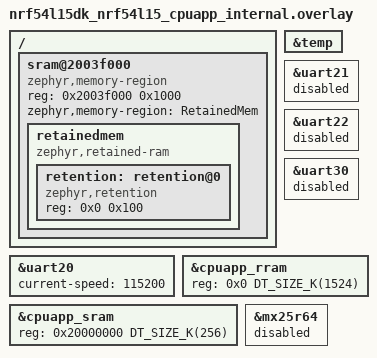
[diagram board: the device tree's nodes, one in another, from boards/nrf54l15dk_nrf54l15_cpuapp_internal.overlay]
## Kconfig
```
mainmenu "nRF54 Soil Moisture Sensor Configuration"

config APP_TEMPERATURE_MONITORING
	bool "Enable temperature monitoring"
	default y
	select SENSOR
	help
	  Enable internal die temperature sensor monitoring.

config APP_MEASUREMENT_INTERVAL_SEC
	int "Measurement interval (seconds)"
	default 300
	help
	  Time between periodic measurements. Device sleeps between readings.


if OPENTHREAD

choice OPENTHREAD_NORDIC_LIBRARY_CONFIGURATION
	default OPENTHREAD_NORDIC_LIBRARY_MTD
endchoice

choice OPENTHREAD_DEVICE_TYPE
	default OPENTHREAD_MTD
endchoice

endif # OPENTHREAD

source "${ZEPHYR_CONNECTEDHOMEIP_MODULE_DIR}/config/nrfconnect/chip-module/Kconfig.features"
source "${ZEPHYR_CONNECTEDHOMEIP_MODULE_DIR}/config/nrfconnect/chip-module/Kconfig.defaults"
source "Kconfig.zephyr"
```

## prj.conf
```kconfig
# nRF54 Soil Moisture Sensor - Debug Configuration
# Development build with full logging

# Application features
CONFIG_APP_TEMPERATURE_MONITORING=y
CONFIG_APP_MEASUREMENT_INTERVAL_SEC=10

# Enable CHIP
CONFIG_CHIP=y
CONFIG_CHIP_DEVICE_PRODUCT_ID=32781
CONFIG_CHIP_PROJECT_CONFIG="src/chip_project_config.h"
CONFIG_STD_CPP17=y
CONFIG_THREAD_NAME=y
CONFIG_MPU_STACK_GUARD=y
CONFIG_CHIP_LIB_SHELL=y
CONFIG_CHIP_ENABLE_PAIRING_AUTOSTART=y

# Enable Intermittently Connected Device support,
# with Long Idle Time to reduce power usage
CONFIG_CHIP_ENABLE_ICD_SUPPORT=y
CONFIG_CHIP_ICD_LIT_SUPPORT=y

# Enable Matter extended announcement and increase duration to 1 hour
CONFIG_CHIP_BLE_EXT_ADVERTISING=y
CONFIG_CHIP_BLE_ADVERTISING_DURATION=60

# OpenThread shell for debugging
CONFIG_OPENTHREAD_SHELL=y
CONFIG_SHELL_BACKEND_SERIAL_RX_RING_BUFFER_SIZE=256

# GRTC timer for wakeup from System OFF
CONFIG_NRF_GRTC_TIMER=y

# RAM retention in System OFF
CONFIG_RETAINED_MEM=y
CONFIG_RETAINED_MEM_MUTEX_FORCE_DISABLE=y
CONFIG_RETENTION=y
CONFIG_CRC=y

# Hardware info for reset cause detection
CONFIG_HWINFO=y

# Power Management
CONFIG_PM_DEVICE=y
CONFIG_PM_DEVICE_RUNTIME=y

# System Off (deep sleep)
CONFIG_POWEROFF=y

# Memory footprint
CONFIG_HEAP_MEM_POOL_SIZE=1024
CONFIG_IDLE_STACK_SIZE=256

# Minimal libc
CONFIG_MINIMAL_LIBC=y

# Console for debugging
CONFIG_CONSOLE=y
CONFIG_UART_CONSOLE=y

# Configure UART async logging and shell
CONFIG_LOG=y
CONFIG_LOG_MODE_DEFERRED=y
CONFIG_LOG_PROCESS_THREAD_STACK_SIZE=1024
CONFIG_LOG_BUFFER_SIZE=4096
CONFIG_LOG_FUNC_NAME_PREFIX_DBG=n
CONFIG_SHELL=y
CONFIG_SHELL_LOG_BACKEND=y

# Size optimizations
CONFIG_SIZE_OPTIMIZATIONS=y
CONFIG_LTO=y

# Matter/CHIP size optimizations
CONFIG_CHIP_LOG_SIZE_OPTIMIZATION=y
CONFIG_CHIP_TASK_STACK_SIZE=6144
CONFIG_CHIP_MALLOC_SYS_HEAP_SIZE=8192
CONFIG_CHIP_SYSTEM_PACKETBUFFER_POOL_SIZE=10
CONFIG_CHIP_OTA_REQUESTOR_BUFFER_SIZE=512

# Reduce BLE buffers
CONFIG_BT_BUF_EVT_RX_COUNT=8
CONFIG_BT_BUF_ACL_RX_COUNT=4
CONFIG_BT_BUF_CMD_TX_COUNT=4

# TODO Not sure why this is needed, without it we stack overflow main upon commisioning
CONFIG_MAIN_STACK_SIZE=8196
CONFIG_MATTER_LOG_LEVEL_DBG=y
```

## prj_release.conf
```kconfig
# nRF54 Soil Moisture Sensor - Release Configuration Overrides
# Optimized to reduce power consumption

# Application features
CONFIG_APP_MEASUREMENT_INTERVAL_SEC=60

# Disable all logging
CONFIG_LOG=n

# Disable Matter/CHIP logging (0 = OFF)
CONFIG_CHIP_APP_LOG_LEVEL=0

# Disable console/UART
CONFIG_CONSOLE=n
CONFIG_UART_CONSOLE=n
CONFIG_SERIAL=n

# Disable assertions
CONFIG_ASSERT=n
CONFIG_ASSERT_VERBOSE=n

# Disable debug features
CONFIG_DEBUG=n
CONFIG_DEBUG_INFO=n
CONFIG_THREAD_NAME=n
CONFIG_PRINTK=n
CONFIG_BOOT_BANNER=n

# Disable shell
CONFIG_SHELL=n
CONFIG_CHIP_LIB_SHELL=n
```

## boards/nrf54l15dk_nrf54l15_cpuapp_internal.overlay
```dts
/ {
	/* Retained RAM for state across System OFF */
	sram@2003f000 {
		compatible = "zephyr,memory-region", "mmio-sram";
		reg = <0x2003f000 0x1000>;
		zephyr,memory-region = "RetainedMem";
		status = "okay";

		retainedmem {
			compatible = "zephyr,retained-ram";
			status = "okay";
			#address-cells = <1>;
			#size-cells = <1>;

			retention: retention@0 {
				compatible = "zephyr,retention";
				status = "okay";
				reg = <0x0 0x100>;
			};
		};
	};
};

/* Enable internal temperature sensor */
&temp {
	status = "okay";
};

/* Keep UART20 for console (it's the default console) */
&uart20 {
	status = "okay";
	current-speed = <115200>;
};

/* Disable unused peripherals to save power */
&uart21 {
	status = "disabled";
};

&uart22 {
	status = "disabled";
};

&uart30 {
	status = "disabled";
};

// restore full RRAM and SRAM space - by default some parts are dedicated to FLRP
&cpuapp_rram {
	reg = <0x0 DT_SIZE_K(1524)>;
};

&cpuapp_sram {
	reg = <0x20000000 DT_SIZE_K(256)>;
	ranges = <0x0 0x20000000  0x40000>;
};

// Disable external flash
&mx25r64 {
	status = "disabled";
};
```

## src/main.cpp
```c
/*
 * nRF54 Soil Moisture Sensor - Main Entry Point
 */

#include "app_task.h"

#include <zephyr/kernel.h>
#include <zephyr/logging/log.h>
#include <zephyr/sys/printk.h>

LOG_MODULE_REGISTER(app, CONFIG_CHIP_APP_LOG_LEVEL);

int main()
{
	LOG_INF("Starting Soil Sensor");
	k_sleep(K_MSEC(100));

	CHIP_ERROR err = AppTask::Instance().StartApp();

	LOG_ERR("Exited with code %" CHIP_ERROR_FORMAT, err.Format());
	return err == CHIP_NO_ERROR ? EXIT_SUCCESS : EXIT_FAILURE;
}
```

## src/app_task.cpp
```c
/*
 * nRF54 Soil Moisture Sensor - Matter Application Task
 */

#include "app_task.h"

#include <app/server/Server.h>
#include <app/clusters/network-commissioning/network-commissioning.h>
#include <app/reporting/reporting.h>
#include <app/util/attribute-storage.h>
#include <app-common/zap-generated/attributes/Accessors.h>
#include <credentials/DeviceAttestationCredsProvider.h>
#include <credentials/examples/DeviceAttestationCredsExample.h>
#include <data-model-providers/codegen/Instance.h>
#include <inet/EndPointStateOpenThread.h>
#include <lib/core/CHIPError.h>
#include <lib/support/CodeUtils.h>
#include <platform/CHIPDeviceLayer.h>
#include <platform/OpenThread/GenericNetworkCommissioningThreadDriver.h>
#include <platform/ThreadStackManager.h>

#include "zap-generated/endpoint_config.h"

#include <zephyr/drivers/sensor.h>
#include <zephyr/kernel.h>
#include <zephyr/logging/log.h>
#include <zephyr/sys/printk.h>

LOG_MODULE_REGISTER(app_task, CONFIG_CHIP_APP_LOG_LEVEL);

using namespace ::chip;
using namespace ::chip::DeviceLayer;

namespace {
chip::app::Clusters::NetworkCommissioning::InstanceAndDriver<
	chip::DeviceLayer::NetworkCommissioning::GenericThreadDriver> sThreadNetworkDriver(0);

const struct device *temp_dev;
struct k_work_delayable temp_work;

void LockOpenThreadTask()
{
	ThreadStackMgr().LockThreadStack();
}

void UnlockOpenThreadTask()
{
	ThreadStackMgr().UnlockThreadStack();
}

void ReadTemperatureSensor(struct k_work *work)
{
	struct sensor_value temp_value;

	if (sensor_sample_fetch(temp_dev) == 0) {
		if (sensor_channel_get(temp_dev, SENSOR_CHAN_DIE_TEMP, &temp_value) == 0) {
			int16_t temp_hundredths = (temp_value.val1 * 100) + (temp_value.val2 / 10000);
			temp_hundredths -= 300; // 3 degC offset for IC self-heating

			LOG_INF("Raw Temperature: %d.%02d C (Adjusted Matter: %d)",
				temp_value.val1, temp_value.val2 / 10000, temp_hundredths);

			chip::DeviceLayer::PlatformMgr().LockChipStack();
			chip::app::Clusters::TemperatureMeasurement::Attributes::MeasuredValue::Set(
				1, chip::app::DataModel::Nullable<int16_t>(temp_hundredths));
			chip::DeviceLayer::PlatformMgr().UnlockChipStack();
		} else {
			LOG_ERR("Failed to get temperature value");
		}
	} else {
		LOG_ERR("Failed to fetch temperature sample");
	}

	k_work_schedule(&temp_work, K_SECONDS(CONFIG_APP_MEASUREMENT_INTERVAL_SEC));
}
}

CHIP_ERROR AppTask::Init()
{
	ReturnErrorOnFailure(PlatformMgr().InitChipStack());

	ReturnErrorOnFailure(ThreadStackMgr().InitThreadStack());

	sThreadNetworkDriver.Init();

	chip::Credentials::SetDeviceAttestationCredentialsProvider(
		chip::Credentials::Examples::GetExampleDACProvider());

	static chip::CommonCaseDeviceServerInitParams initParams;

	chip::Inet::EndPointStateOpenThread::OpenThreadEndpointInitParam nativeParams;
	nativeParams.lockCb = LockOpenThreadTask;
	nativeParams.unlockCb = UnlockOpenThreadTask;
	nativeParams.openThreadInstancePtr = ThreadStackMgrImpl().OTInstance();
	initParams.endpointNativeParams = static_cast<void *>(&nativeParams);

	ReturnErrorOnFailure(initParams.InitializeStaticResourcesBeforeServerInit());

	initParams.dataModelProvider = chip::app::CodegenDataModelProviderInstance(initParams.persistentStorageDelegate);

	ReturnErrorOnFailure(chip::Server::GetInstance().Init(initParams));

	ConfigurationMgr().LogDeviceConfig();

	temp_dev = DEVICE_DT_GET(DT_NODELABEL(temp));
	if (!device_is_ready(temp_dev)) {
		LOG_ERR("Temperature sensor not ready");
		return CHIP_ERROR_INTERNAL;
	}

	k_work_init_delayable(&temp_work, ReadTemperatureSensor);
	k_work_schedule(&temp_work, K_MSEC(100));

	return CHIP_NO_ERROR;
}

CHIP_ERROR AppTask::StartApp()
{
	ReturnErrorOnFailure(Init());

	LOG_INF("Matter server initialized");

	PlatformMgr().RunEventLoop();

	return CHIP_NO_ERROR;
}
```
